# R7FA2L1AB register map
Vendor: Renesas Electronics Corporation; Series: RA2L1; File version: 1.30.00
CPU: CM23 r1p0, little endian, MPU, no FPU, VTOR, 2 interrupt priority bits, 32 interrupts
Registers are 8-bit, read-write, reset 0x0 unless marked. A register's access mark holds for its fields unless they carry their own. Offsets are from the block's base; [hi:lo] are bit positions; {n}, {i} and the like mark numbered series; 'fields as' and 'values as' point back to an identical list.

## PORT0 — Port 0 Control Registers
Base 0x40040000
Same registers: PORT3 0x40040060, PORT4 0x40040080, PORT5 0x400400A0, PORT6 0x400400C0, PORT7 0x400400E0, PORT8 0x40040100
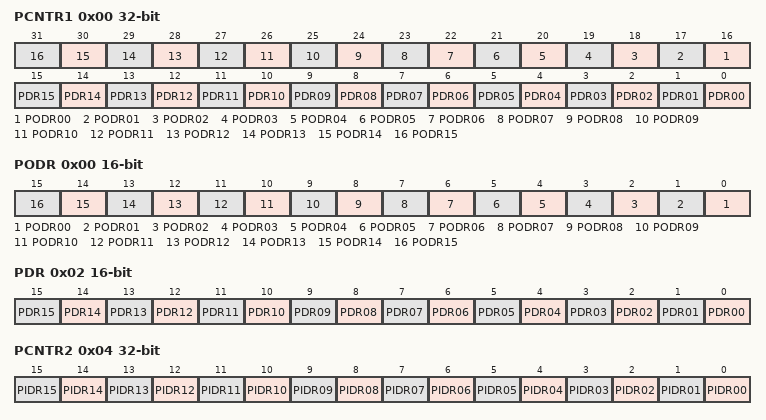
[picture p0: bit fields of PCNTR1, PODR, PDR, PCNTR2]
0x00 PCNTR1 32-bit — Port Control Register 1
  [n+16] PODR{n:02} (n=0..15) — Pmn Output Data
    0=Low output; 1=High output
  [n] PDR{n:02} (n=0..15) — Pmn Direction
    0=Input (functions as an input pin); 1=Output (functions as an output pin)
0x00 PODR 16-bit (alternate view of PCNTR1) — Port Control Register 1
  [all] fields
    0=Low output; 1=High output
  [n] PODR{n:02} (n=0..15) — Pmn Output Data
0x02 PDR 16-bit (alternate view of PCNTR1) — Port Control Register 1
  [all] fields
    values as PCNTR1.PDR00
  [n] PDR{n:02} (n=0..15) — Pmn Direction
0x04 PCNTR2 32-bit ro (reset mask 0xFFFF0000) — Port Control Register 2
  [all] fields
    0=Low level; 1=High level
  [n] PIDR{n:02} (n=0..15) — Pmn State
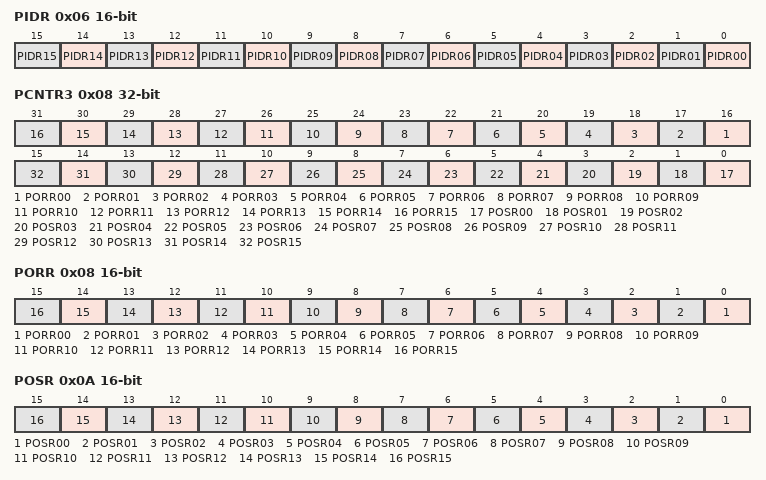
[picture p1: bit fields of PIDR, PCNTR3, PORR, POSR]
0x06 PIDR 16-bit ro reset not defined (alternate view of PCNTR2) — Port Control Register 2
  fields as PCNTR2
0x08 PCNTR3 32-bit wo — Port Control Register 3
  [n+16] PORR{n:02} (n=0..15) — Pmn Output Reset
    0=No effect on output; 1=Low output
  [n] POSR{n:02} (n=0..15) — Pmn Output Set
    0=No effect on output; 1=High output
0x08 PORR 16-bit wo (alternate view of PCNTR3) — Port Control Register 3
  [all] fields
    0=No effect on output; 1=Low output
  [n] PORR{n:02} (n=0..15) — Pmn Output Reset
0x0A POSR 16-bit wo (alternate view of PCNTR3) — Port Control Register 3
  [all] fields
    0=No effect on output; 1=High output
  [n] POSR{n:02} (n=0..15) — Pmn Output Set

## PORT1 — Port 1 Control Registers
Base 0x40040020
Same registers: PORT2 0x40040040
Registers as PORT0; these are added or differ:
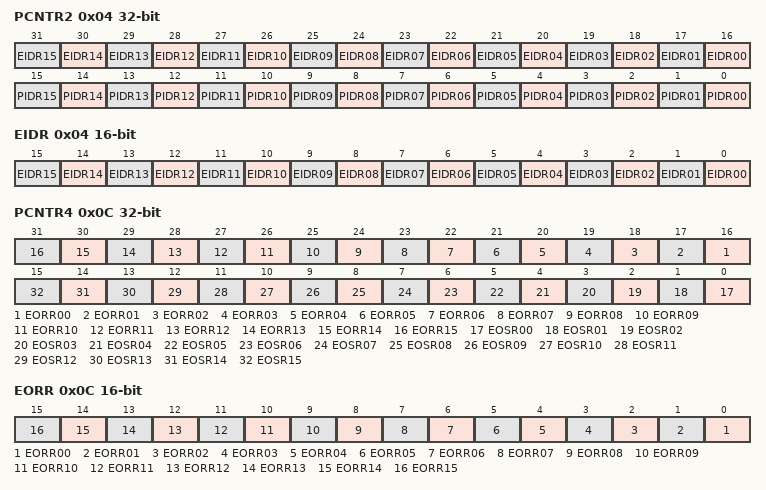
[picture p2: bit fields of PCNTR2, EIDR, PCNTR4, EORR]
0x04 PCNTR2 32-bit ro (reset mask 0xFFFF0000) — Port Control Register 2
  [n+16] EIDR{n:02} (n=0..15) — Port Event Input Data
    0=Low input; 1=High input
  [n] PIDR{n:02} (n=0..15) — Pmn State
    0=Low level; 1=High level
0x04 EIDR 16-bit ro (alternate view of PCNTR2) — Port Control Register 2
  [all] fields
    0=Low input; 1=High input
  [n] EIDR{n:02} (n=0..15) — Port Event Input Data
0x0C PCNTR4 32-bit — Port Control Register 4
  [n+16] EORR{n:02} (n=0..15) — Pmn Event Output Reset
    0=No effect on output; 1=Low output
  [n] EOSR{n:02} (n=0..15) — Pmn Event Output Set
    0=No effect on output; 1=High output
0x0C EORR 16-bit (alternate view of PCNTR4) — Port Control Register 4
  [all] fields
    0=No effect on output; 1=Low output
  [n] EORR{n:02} (n=0..15) — Pmn Event Output Reset
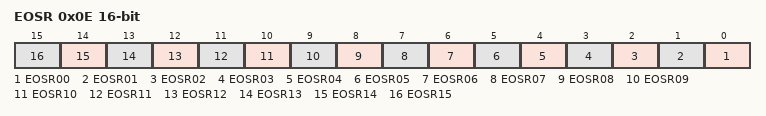
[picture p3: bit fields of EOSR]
0x0E EOSR 16-bit (alternate view of PCNTR4) — Port Control Register 4
  [all] fields
    0=No effect on output; 1=High output
  [n] EOSR{n:02} (n=0..15) — Pmn Event Output Set

## ELC — Event Link Controller
Base 0x40041000
0x00 ELCR — Event Link Controller Register
  [7] ELCON — All Event Link Enable
    0=ELC function is disabled; 1=ELC function is enabled
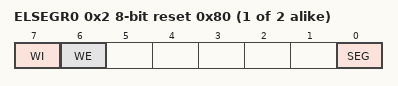
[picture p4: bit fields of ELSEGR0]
{0x2+2i} ELSEGR{i} (i=0..1) reset 0x80 — Event Link Software Event Generation Register {i}
  [7] WI wo — ELSEGR Register Write Disable
    0=Write to ELSEGR register enabled; 1=Write to ELSEGR register disabled
  [6] WE — SEG Bit Write Enable
    0=Write to SEG bit disabled; 1=Write to SEG bit enabled
  [0] SEG wo — Software Event Generation
    0=Normal operation; 1=Software event is generated
{0x10+4i} ELSR{i} (i=0..3) 16-bit — Event Link Setting Register {i}
  [7:0] ELS — Event Link Select
{0x10+4i} ELSR{i} (i=8..9) 16-bit — Event Link Setting Register {i}
  [7:0] ELS — Event Link Select
0x40 ELSR12 16-bit — Event Link Setting Register 12
  [7:0] ELS — Event Link Select
{0x10+4i} ELSR{i} (i=14..15) 16-bit — Event Link Setting Register {i}
  [7:0] ELS — Event Link Select
0x58 ELSR18 16-bit — Event Link Setting Register 18
  [7:0] ELS — Event Link Select
